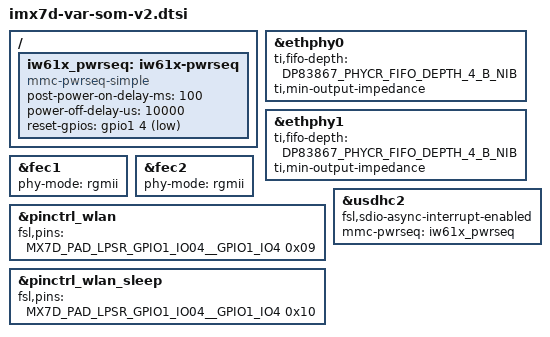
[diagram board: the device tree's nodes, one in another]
// SPDX-License-Identifier: GPL-2.0+ OR MIT
//
// Copyright (C) 2026 Variscite Ltd.

#include <dt-bindings/net/ti-dp83867.h>

/ {
	iw61x_pwrseq: iw61x-pwrseq {
		compatible = "mmc-pwrseq-simple";
		post-power-on-delay-ms = <100>;
		power-off-delay-us = <10000>;
		reset-gpios = <&gpio1 4 GPIO_ACTIVE_LOW>;
		status = "okay";
	};
};

&ethphy0 {
	ti,fifo-depth = <DP83867_PHYCR_FIFO_DEPTH_4_B_NIB>;
	ti,min-output-impedance;
};

&ethphy1 {
	ti,fifo-depth = <DP83867_PHYCR_FIFO_DEPTH_4_B_NIB>;
	ti,min-output-impedance;
};

&fec1 {
	phy-mode = "rgmii";
};

&fec2 {
	phy-mode = "rgmii";
};

&pinctrl_wlan {
	fsl,pins = <
		MX7D_PAD_LPSR_GPIO1_IO04__GPIO1_IO4	0x09 /* WLAN_EN */
	>;
};

&pinctrl_wlan_sleep {
	fsl,pins = <
		MX7D_PAD_LPSR_GPIO1_IO04__GPIO1_IO4	0x10 /* WLAN_EN */
	>;
};

/* WiFi */
&usdhc2 {
	fsl,sdio-async-interrupt-enabled;
	mmc-pwrseq = <&iw61x_pwrseq>;

	/delete-node/ bcrmf@1;
};
